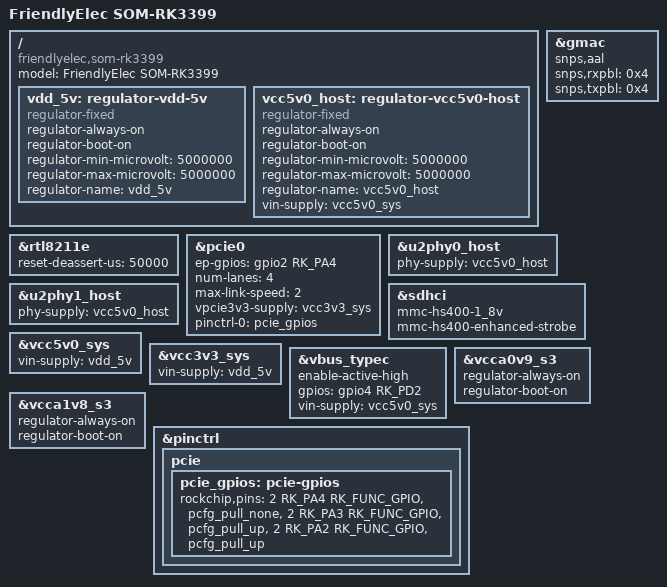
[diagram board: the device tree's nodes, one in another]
// SPDX-License-Identifier: (GPL-2.0+ OR MIT)
/*
 * FriendlyElec SOM-RK3399 board device tree source
 * Copyright (c) 2020 FriendlyElec Computer Tech. Co., Ltd.
 */

/dts-v1/;
#include "rk3399-nanopi4.dtsi"

/ {
	model = "FriendlyElec SOM-RK3399";
	compatible = "friendlyelec,som-rk3399", "rockchip,rk3399";

	/* SOM-RK3399 is powered directly from a 5V supply (no 12V input) */
	vdd_5v: regulator-vdd-5v {
		compatible = "regulator-fixed";
		regulator-always-on;
		regulator-boot-on;
		regulator-min-microvolt = <5000000>;
		regulator-max-microvolt = <5000000>;
		regulator-name = "vdd_5v";
	};

	/* USB host port power supply (always-on, no GPIO control on SOM) */
	vcc5v0_host: regulator-vcc5v0-host {
		compatible = "regulator-fixed";
		regulator-always-on;
		regulator-boot-on;
		regulator-min-microvolt = <5000000>;
		regulator-max-microvolt = <5000000>;
		regulator-name = "vcc5v0_host";
		vin-supply = <&vcc5v0_sys>;
	};
};

&gmac {
	snps,aal;
	snps,rxpbl = <0x4>;
	snps,txpbl = <0x4>;
};

&rtl8211e {
	reset-deassert-us = <50000>;
};

&pcie0 {
	ep-gpios = <&gpio2 RK_PA4 GPIO_ACTIVE_HIGH>;
	num-lanes = <4>;
	max-link-speed = <2>;
	vpcie3v3-supply = <&vcc3v3_sys>;
	pinctrl-names = "default";
	pinctrl-0 = <&pcie_gpios>;
};

/* USB host port power supply */
&u2phy0_host {
	phy-supply = <&vcc5v0_host>;
};

&u2phy1_host {
	phy-supply = <&vcc5v0_host>;
};

&sdhci {
	mmc-hs400-1_8v;
	mmc-hs400-enhanced-strobe;
};

/* Power chain: SOM is powered from 5V input directly */
&vcc5v0_sys {
	vin-supply = <&vdd_5v>;
};

&vcc3v3_sys {
	vin-supply = <&vdd_5v>;
};

/* Type-C USB OTG VBUS enable (SOM has Type-C via FUSB302) */
&vbus_typec {
	enable-active-high;
	gpios = <&gpio4 RK_PD2 GPIO_ACTIVE_HIGH>;
	vin-supply = <&vcc5v0_sys>;
};

/* HDMI PHY power supplies (vcca0v9_s3 and vcca1v8_s3) */
&vcca0v9_s3 {
	regulator-always-on;
	regulator-boot-on;
};

&vcca1v8_s3 {
	regulator-always-on;
	regulator-boot-on;
};

&pinctrl {
	pcie {
		pcie_gpios: pcie-gpios {
			rockchip,pins =
				<2 RK_PA4 RK_FUNC_GPIO &pcfg_pull_none>,
				<2 RK_PA3 RK_FUNC_GPIO &pcfg_pull_up>,
				<2 RK_PA2 RK_FUNC_GPIO &pcfg_pull_up>;
		};
	};
};
